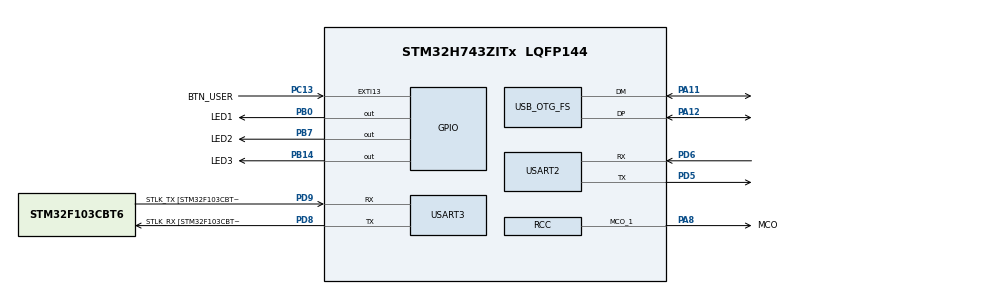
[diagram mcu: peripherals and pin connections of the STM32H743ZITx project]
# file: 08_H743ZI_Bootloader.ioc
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Mcu.Family=STM32H7
Mcu.Name=STM32H743ZITx
Mcu.Package=LQFP144
NVIC.EXTI15_10_IRQn=true\:0\:0\:false\:false\:true\:true\:true
NVIC.OTG_FS_IRQn=true\:0\:0\:false\:false\:true\:false\:true
NVIC.PriorityGroup=NVIC_PRIORITYGROUP_4
NVIC.USART2_IRQn=true\:0\:0\:false\:false\:true\:true\:true
PA11.Mode=Device_Only
PA11.Signal=USB_OTG_FS_DM
PA12.Mode=Device_Only
PA12.Signal=USB_OTG_FS_DP
PA8.GPIO_Label=MCO
PA8.GPIO_PuPd=GPIO_PULLUP
PA8.Mode=Clock-out-1
PA8.Signal=RCC_MCO_1
PB0.GPIO_Label=LED1
PB0.GPIO_PuPd=GPIO_PULLUP
PB0.Signal=GPIO_Output
PB14.GPIO_Label=LED3
PB14.GPIO_PuPd=GPIO_PULLUP
PB14.Signal=GPIO_Output
PB7.GPIO_Label=LED2
PB7.GPIO_PuPd=GPIO_PULLUP
PB7.Signal=GPIO_Output
PC13.GPIO_Label=BTN_USER
PC13.Signal=GPXTI13
PC14-OSC32_IN\ (OSC32_IN).Mode=LSE-External-Oscillator
PC14-OSC32_IN\ (OSC32_IN).Signal=RCC_OSC32_IN
PC15-OSC32_OUT\ (OSC32_OUT).Mode=LSE-External-Oscillator
PC15-OSC32_OUT\ (OSC32_OUT).Signal=RCC_OSC32_OUT
PD5.Mode=Asynchronous
PD5.Signal=USART2_TX
PD6.Mode=Asynchronous
PD6.Signal=USART2_RX
PD8.GPIO_Label=STLK_RX [STM32F103CBT6_PA3]
PD8.Mode=Asynchronous
PD8.Signal=USART3_TX
PD9.GPIO_Label=STLK_TX [STM32F103CBT6_PA2]
PD9.Mode=Asynchronous
PD9.Signal=USART3_RX
PH0-OSC_IN\ (PH0).Mode=HSE-External-Oscillator
PH0-OSC_IN\ (PH0).Signal=RCC_OSC_IN
PH1-OSC_OUT\ (PH1).Mode=HSE-External-Oscillator
PH1-OSC_OUT\ (PH1).Signal=RCC_OSC_OUT
ProjectManager.HeapSize=0x2000
ProjectManager.StackSize=0x2000
ProjectManager.TargetToolchain=EWARM V8
RCC.ADCFreq_Value=16125000
RCC.APB1Freq_Value=100000000
RCC.APB2Freq_Value=100000000
RCC.APB3Freq_Value=100000000
RCC.APB4Freq_Value=100000000
RCC.CortexFreq_Value=400000000
RCC.D1PPRE=RCC_APB3_DIV2
RCC.D2PPRE1=RCC_APB1_DIV2
RCC.D2PPRE2=RCC_APB2_DIV2
RCC.D3PPRE=RCC_APB4_DIV2
RCC.DIVM1=1
RCC.DIVN1=100
RCC.HCLKFreq_Value=200000000
RCC.HPRE=RCC_HCLK_DIV2
RCC.HSE_VALUE=8000000
RCC.PLL1_VCI_Range=RCC_PLL1VCIRANGE_3
RCC.PLL2FRACN=0
RCC.PLL3FRACN=0
RCC.PLLFRACN=0
RCC.PLLSourceVirtual=RCC_PLLSOURCE_HSE
RCC.SYSCLKFreq_VALUE=400000000
RCC.SYSCLKSource=RCC_SYSCLKSOURCE_PLLCLK
RCC.USBCLockSelection=RCC_USBCLKSOURCE_HSI48
RCC.USBFreq_Value=48000000
USART2.VirtualMode-Asynchronous=VM_ASYNC
USART3.VirtualMode-Asynchronous=VM_ASYNC
USB_DEVICE.CLASS_NAME_FS=DFU
USB_DEVICE.USBD_DFU_APP_DEFAULT_ADD-DFU_FS=0x08020000
USB_DEVICE.USBD_DFU_MEDIA-DFU_FS=@Internal Flash   /0x08000000/01*128Ka,7*128Kg
USB_DEVICE.VirtualMode-DFU_FS=Dfu
USB_DEVICE.VirtualModeFS=Dfu_FS
USB_OTG_FS.VirtualMode=Device_Only
VP_USB_DEVICE_VS_USB_DEVICE_DFU_FS.Mode=DFU_FS
board=custom

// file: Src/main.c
/* USER CODE BEGIN Header */
/**
  ******************************************************************************
  * @file           : main.c
  * @brief          : Main program body
  ******************************************************************************
  * @attention
  *
  * <h2><center>&copy; Copyright (c) 2019 STMicroelectronics.
  * All rights reserved.</center></h2>
  *
  * This software component is licensed by ST under Ultimate Liberty license
  * SLA0044, the "License"; You may not use this file except in compliance with
  * the License. You may obtain a copy of the License at:
  *                             www.st.com/SLA0044
  *
  ******************************************************************************
  */
/* USER CODE END Header */

#include "main.h"
#include "usart.h"
#include "usb_device.h"
#include "gpio.h"

/* USER CODE BEGIN Includes */
#include <string.h>
#include "usbd_dfu.h"
#include "main_process.h"
/* USER CODE END Includes */

void SystemClock_Config(void);

int main(void)
{

  /* MCU Configuration--------------------------------------------------------*/

  /* Reset of all peripherals, Initializes the Flash interface and the Systick. */
  HAL_Init();

  /* Configure the system clock */
  SystemClock_Config();

  /* Initialize all configured peripherals */
  MX_GPIO_Init();
  MX_USART2_UART_Init();
  MX_USART3_UART_Init();
  /* USER CODE BEGIN 2 */

	jprintf( "\r\n\nStart Bootloader...(%s)\r\n", __DATE__ );

	MainProcess();
  /* USER CODE END 2 */

  /* Infinite loop */
  while (1)
  {

  }
}

void SystemClock_Config(void)
{
  RCC_OscInitTypeDef RCC_OscInitStruct = {0};
  RCC_ClkInitTypeDef RCC_ClkInitStruct = {0};
  RCC_PeriphCLKInitTypeDef PeriphClkInitStruct = {0};

  /** Supply configuration update enable
  */
  MODIFY_REG(PWR->CR3, PWR_CR3_SCUEN, 0);
  /** Configure the main internal regulator output voltage
  */
  __HAL_PWR_VOLTAGESCALING_CONFIG(PWR_REGULATOR_VOLTAGE_SCALE1);

  while ((PWR->D3CR & (PWR_D3CR_VOSRDY)) != PWR_D3CR_VOSRDY)
  {

  }
  /** Initializes the CPU, AHB and APB busses clocks
  */
  RCC_OscInitStruct.OscillatorType = RCC_OSCILLATORTYPE_HSI48|RCC_OSCILLATORTYPE_HSE;
  RCC_OscInitStruct.HSEState = RCC_HSE_ON;
  RCC_OscInitStruct.HSI48State = RCC_HSI48_ON;
  RCC_OscInitStruct.PLL.PLLState = RCC_PLL_ON;
  RCC_OscInitStruct.PLL.PLLSource = RCC_PLLSOURCE_HSE;
  RCC_OscInitStruct.PLL.PLLM = 1;
  RCC_OscInitStruct.PLL.PLLN = 100;
  RCC_OscInitStruct.PLL.PLLP = 2;
  RCC_OscInitStruct.PLL.PLLQ = 2;
  RCC_OscInitStruct.PLL.PLLR = 2;
  RCC_OscInitStruct.PLL.PLLRGE = RCC_PLL1VCIRANGE_3;
  RCC_OscInitStruct.PLL.PLLVCOSEL = RCC_PLL1VCOWIDE;
  RCC_OscInitStruct.PLL.PLLFRACN = 0;
  if (HAL_RCC_OscConfig(&RCC_OscInitStruct) != HAL_OK)
  {
    Error_Handler();
  }
  /** Initializes the CPU, AHB and APB busses clocks
  */
  RCC_ClkInitStruct.ClockType = RCC_CLOCKTYPE_HCLK|RCC_CLOCKTYPE_SYSCLK
                              |RCC_CLOCKTYPE_PCLK1|RCC_CLOCKTYPE_PCLK2
                              |RCC_CLOCKTYPE_D3PCLK1|RCC_CLOCKTYPE_D1PCLK1;
  RCC_ClkInitStruct.SYSCLKSource = RCC_SYSCLKSOURCE_PLLCLK;
  RCC_ClkInitStruct.SYSCLKDivider = RCC_SYSCLK_DIV1;
  RCC_ClkInitStruct.AHBCLKDivider = RCC_HCLK_DIV2;
  RCC_ClkInitStruct.APB3CLKDivider = RCC_APB3_DIV2;
  RCC_ClkInitStruct.APB1CLKDivider = RCC_APB1_DIV2;
  RCC_ClkInitStruct.APB2CLKDivider = RCC_APB2_DIV2;
  RCC_ClkInitStruct.APB4CLKDivider = RCC_APB4_DIV2;

  if (HAL_RCC_ClockConfig(&RCC_ClkInitStruct, FLASH_LATENCY_2) != HAL_OK)
  {
    Error_Handler();
  }
  PeriphClkInitStruct.PeriphClockSelection = RCC_PERIPHCLK_USART3|RCC_PERIPHCLK_USART2
                              |RCC_PERIPHCLK_USB;
  PeriphClkInitStruct.Usart234578ClockSelection = RCC_USART234578CLKSOURCE_D2PCLK1;
  PeriphClkInitStruct.UsbClockSelection = RCC_USBCLKSOURCE_HSI48;
  if (HAL_RCCEx_PeriphCLKConfig(&PeriphClkInitStruct) != HAL_OK)
  {
    Error_Handler();
  }
  HAL_RCC_MCOConfig(RCC_MCO1, RCC_MCO1SOURCE_PLL1QCLK, RCC_MCODIV_10);
}

void Error_Handler(void)
{
}

/************************ (C) COPYRIGHT STMicroelectronics *****END OF FILE****/
